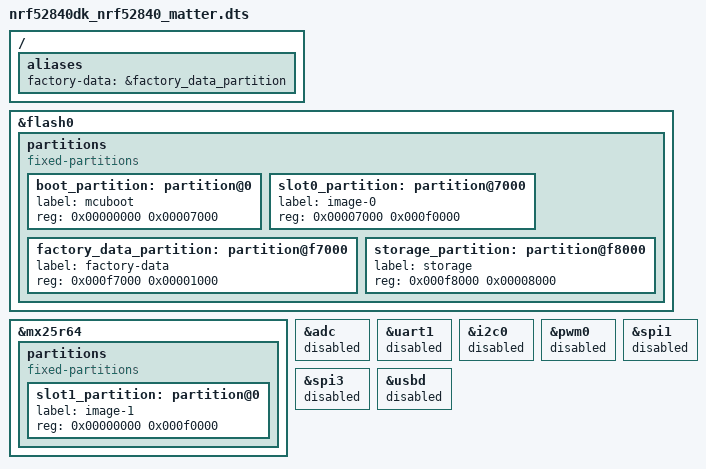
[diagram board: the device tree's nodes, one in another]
/*
 * Copyright (c) 2025 Nordic Semiconductor ASA
 *
 * SPDX-License-Identifier: LicenseRef-Nordic-5-Clause
 */

#include <../boards/nordic/nrf52840dk/nrf52840dk_nrf52840.dts>

/delete-node/ &boot_partition;
/delete-node/ &slot0_partition;
/delete-node/ &slot1_partition;
/delete-node/ &storage_partition;

/ {
	aliases {
		factory-data = &factory_data_partition;
	};
};

&flash0 {
	partitions {
		compatible = "fixed-partitions";
		#address-cells = <1>;
		#size-cells = <1>;

		boot_partition: partition@0 {
			label = "mcuboot";
			reg = <0x00000000 0x00007000>;
		};

		slot0_partition: partition@7000 {
			label = "image-0";
			reg = <0x00007000 0x000f0000>;
		};

		factory_data_partition: partition@f7000 {
			label = "factory-data";
			reg = <0x000f7000 0x00001000>;
		};

		storage_partition: partition@f8000 {
			label = "storage";
			reg = <0x000f8000 0x00008000>;
		};
	};
};

&mx25r64 {
	partitions {
		compatible = "fixed-partitions";
		#address-cells = <1>;
		#size-cells = <1>;

		slot1_partition: partition@0 {
			label = "image-1";
			reg = <0x00000000 0x000f0000>;
		};
	};
};

/* Disable unused peripherals to reduce power consumption */
&adc {
	status = "disabled";
};

&uart1 {
	status = "disabled";
};

&i2c0 {
	status = "disabled";
};

&pwm0 {
	status = "disabled";
};

&spi1 {
	status = "disabled";
};

&spi3 {
	status = "disabled";
};

&usbd {
	status = "disabled";
};
